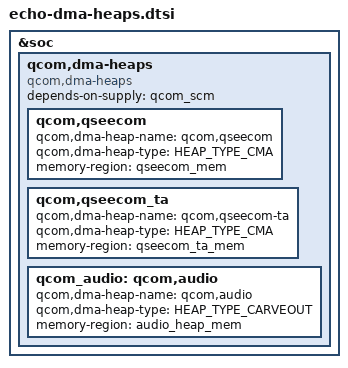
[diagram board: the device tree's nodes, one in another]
// SPDX-License-Identifier: BSD-3-Clause
/*
 * Copyright (c) Qualcomm Technologies, Inc. and/or its subsidiaries.
 */

#include <dt-bindings/arm/qcom_dma_heap_dt_constants.h>

&soc {
	qcom,dma-heaps {
		compatible = "qcom,dma-heaps";
		depends-on-supply = <&qcom_scm>;

		qcom,qseecom {
			qcom,dma-heap-name = "qcom,qseecom";
			qcom,dma-heap-type = <HEAP_TYPE_CMA>;
			memory-region = <&qseecom_mem>;
		};

		qcom,qseecom_ta {
			qcom,dma-heap-name = "qcom,qseecom-ta";
			qcom,dma-heap-type = <HEAP_TYPE_CMA>;
			memory-region = <&qseecom_ta_mem>;
		};

		qcom_audio: qcom,audio {
			qcom,dma-heap-name = "qcom,audio";
			qcom,dma-heap-type = <HEAP_TYPE_CARVEOUT>;
			memory-region = <&audio_heap_mem>;
		};
	};
};
